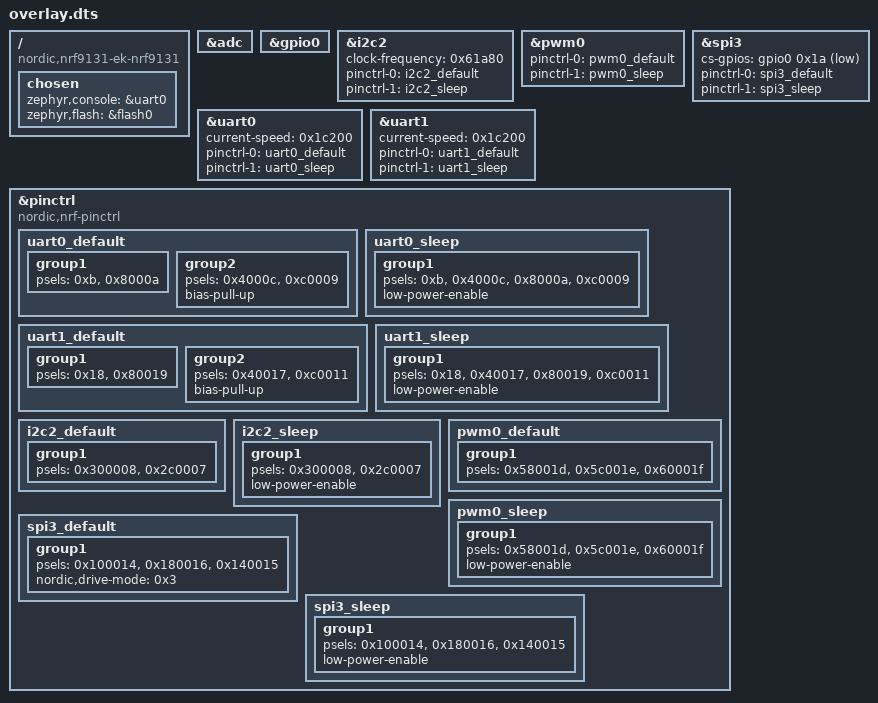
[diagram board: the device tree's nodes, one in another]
/ {
	compatible = "nordic,nrf9131-ek-nrf9131";
	chosen {
		zephyr,console = &uart0;
		zephyr,flash = &flash0;
	};
};
&adc{
	status = "okay";
};
&gpio0{
	status = "okay";
};
&i2c2{
	clock-frequency = < 0x61a80 >;
	status = "okay";
	pinctrl-0 = < &i2c2_default >;
	pinctrl-1 = < &i2c2_sleep >;
	pinctrl-names = "default", "sleep";
};
&pwm0{
	status = "okay";
	pinctrl-0 = < &pwm0_default >;
	pinctrl-1 = < &pwm0_sleep >;
	pinctrl-names = "default", "sleep";
};
&spi3{
	status = "okay";
	cs-gpios = < &gpio0 0x1a 0x1 >;
	pinctrl-0 = < &spi3_default >;
	pinctrl-1 = < &spi3_sleep >;
	pinctrl-names = "default", "sleep";
};
&uart0{
	status = "okay";
	current-speed = < 0x1c200 >;
	pinctrl-0 = < &uart0_default >;
	pinctrl-1 = < &uart0_sleep >;
	pinctrl-names = "default", "sleep";
};
&uart1{
	status = "okay";
	current-speed = < 0x1c200 >;
	pinctrl-0 = < &uart1_default >;
	pinctrl-1 = < &uart1_sleep >;
	pinctrl-names = "default", "sleep";
};
&pinctrl{
	compatible = "nordic,nrf-pinctrl";
	uart0_default: uart0_default {
		group1 {
			psels = < 0xb >, < 0x8000a >;
		};
		group2 {
			psels = < 0x4000c >, < 0xc0009 >;
			bias-pull-up;
		};
	};
	uart0_sleep: uart0_sleep {
		group1 {
			psels = < 0xb >, < 0x4000c >, < 0x8000a >, < 0xc0009 >;
			low-power-enable;
		};
	};
	uart1_default: uart1_default {
		group1 {
			psels = < 0x18 >, < 0x80019 >;
		};
		group2 {
			psels = < 0x40017 >, < 0xc0011 >;
			bias-pull-up;
		};
	};
	uart1_sleep: uart1_sleep {
		group1 {
			psels = < 0x18 >, < 0x40017 >, < 0x80019 >, < 0xc0011 >;
			low-power-enable;
		};
	};
	i2c2_default: i2c2_default {
		group1 {
			psels = < 0x300008 >, < 0x2c0007 >;
		};
	};
	i2c2_sleep: i2c2_sleep {
		group1 {
			psels = < 0x300008 >, < 0x2c0007 >;
			low-power-enable;
		};
	};
	pwm0_default: pwm0_default {
		group1 {
			psels = < 0x58001d >, < 0x5c001e >, < 0x60001f >;
		};
	};
	pwm0_sleep: pwm0_sleep {
		group1 {
			psels = < 0x58001d >, < 0x5c001e >, < 0x60001f >;
			low-power-enable;
		};
	};
	spi3_default: spi3_default {
		group1 {
			psels = < 0x100014 >, < 0x180016 >, < 0x140015 >;
			nordic,drive-mode = < 0x3 >;
		};
	};
	spi3_sleep: spi3_sleep {
		group1 {
			psels = < 0x100014 >, < 0x180016 >, < 0x140015 >;
			low-power-enable;
		};
	};
};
